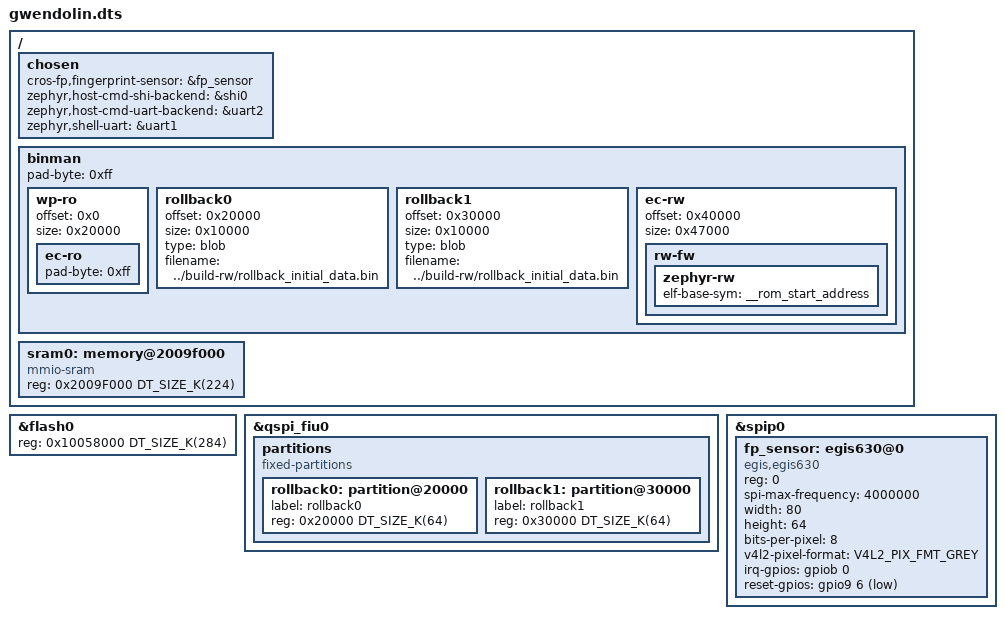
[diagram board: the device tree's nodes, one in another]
/* Copyright 2025 The ChromiumOS Authors.
 * Use of this source code is governed by a BSD-style license that can be
 * found in the LICENSE file.
 */

#include "gpio.dtsi"
#include "gwendolin/rwsig.dtsi"
#include "soc.dtsi"

#include <cros/integrated_fwid.dtsi>

/ {
	chosen {
		cros-fp,fingerprint-sensor = &fp_sensor;
		zephyr,host-cmd-shi-backend = &shi0;
		zephyr,host-cmd-uart-backend = &uart2;
		zephyr,shell-uart = &uart1;
	};

	binman {
		/* First 128 kB (uniform 4 kB sectors) used for RO */
		wp-ro {
			offset = <0x0>;
			size = <0x20000>;
			ec-ro {
				pad-byte = <0xff>;
			};
		};

		/* Two rollback sections (64 kB each) */
		rollback0 {
			offset = <0x20000>;
			size = <0x10000>;
			type = "blob";
			filename = "../build-rw/rollback_initial_data.bin";
		};

		rollback1 {
			offset = <0x30000>;
			size = <0x10000>;
			type = "blob";
			filename = "../build-rw/rollback_initial_data.bin";
		};

		/* 284 kB used for RW - gwendolin ECOS flash size */
		ec-rw {
			offset = <0x40000>;
			size = <0x47000>;
			rw-fw {
				/*
				 * Clang doesn't emit STT_SECTION symbols (also
				 * called 'section symbols'), so 'rom_start'
				 * symbol is not available. Fortunately, Zephyr
				 * linker scripts provide '__rom_start_address'
				 * symbol which points to the beginning of
				 * 'rom_start' section.
				 */
				zephyr-rw {
					elf-base-sym = "__rom_start_address";
				};
			};
		};
		pad-byte = <0xff>;
	};
};

/*
 *           ┌──────────────┐
 *           │   Reserved   │
 *           │     4KB      │
 *           ├──────────────┤0x200D7000
 *           │              │
 *           │              │
 *           │   Data RAM   │
 *           │     224KB    │
 *           │              │
 *           │              │
 * 0x1009F000├──────────────┤0x2009F000
 *           │              │
 *           │              │
 *           │              │
 *           │              │
 *           │   Code RAM   │
 *           │     284KB    │
 *           │              │
 *           │              │
 *           │              │
 *           │              │
 *           │              │
 * 0x10058000└──────────────┘
 */
&flash0 {
    reg = <0x10058000 DT_SIZE_K(284)>;
};

/delete-node/ &sram0;

/ {
	sram0: memory@2009f000 {
		compatible = "mmio-sram";
		reg = <0x2009F000 DT_SIZE_K(224)>;
	};
};

&qspi_fiu0 {
	partitions {
		compatible = "fixed-partitions";
		#address-cells = <1>;
		#size-cells = <1>;

		/* First rollback section */
		rollback0: partition@20000 {
			label = "rollback0";
			reg = <0x20000 DT_SIZE_K(64)>;
		};

		/* Second rollback section */
		rollback1: partition@30000 {
			label = "rollback1";
			reg = <0x30000 DT_SIZE_K(64)>;
		};
	};
};

&spip0 {
	fp_sensor: egis630@0 {
		compatible = "egis,egis630";
		reg = <0>;
		spi-max-frequency = <4000000>;

		width = <80>;
		height = <64>;
		bits-per-pixel = <8>;
		v4l2-pixel-format = "V4L2_PIX_FMT_GREY";

		irq-gpios = <&gpiob 0 GPIO_ACTIVE_HIGH>;
		reset-gpios = <&gpio9 6 GPIO_ACTIVE_LOW>;
	};
};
